# MMCSD register map
Vendor: Texas Instruments
Registers are 32-bit, access per field, no defined reset value unless marked. A register's access mark holds for its fields unless they carry their own. Offsets are as the file gives them; [hi:lo] are bit positions; 'fields as' and 'values as' point back to an identical list.

## MMCSD (part 2 of 2)
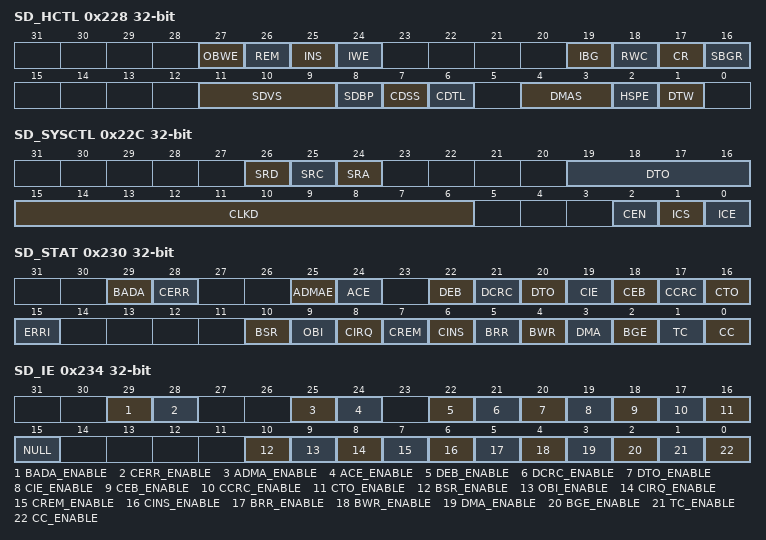
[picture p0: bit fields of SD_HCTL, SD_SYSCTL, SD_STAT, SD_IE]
0x228 SD_HCTL — This register defines the host controls to set power, wake-up and transfer parameters. SD_HCTL[31:24] = Wake-up control. SD_HCTL[23:16] = Block gap control. SD_HCTL[15:8] = Power control. SD_HCTL[7:0] = Host control. If your device does not support MMC cards, then those bits in this register which are meant for MMC card use should be assumed to be reserved.
  [27] OBWE rw — Wake-up event enable for 'out-of-band' Interrupt. [[br]]This bit enables wake-up events for 'out-of-band' assertion. [[br]]Wake-up is generated if the wake-up feature is enabled (SD_SYSCONFIG[2] ENAWAKEUP bit). [[br]]The write to this register is ignored when SD_CON[14] OBIE bit is not set.
    1=en_2_0x1 (Enable wake-up on 'out-of-band' Interrupt); 0=en_1_0x0 (Disable wake-up on 'out-of-band' Interrupt)
  [26] REM rw — Wake-up event enable on SD card removal. [[br]]This bit enables wake-up events for card removal assertion. [[br]]Wake-up is generated if the wake-up feature is enabled (SD_SYSCONFIG[2] ENAWAKEUP bit).
    1=en_2_0x1 (Enable wake-up on card removal); 0=en_1_0x0 (Disable wake-up on card removal)
  [25] INS rw — Wake-up event enable on SD card insertion This bit enables wake-up events for card insertion assertion. [[br]]Wake-up is generated if the wake-up feature is enabled (SD_SYSCONFIG[2] ENAWAKEUP bit).
    1=en_2_0x1 (Enable wake-up on card insertion); 0=en_1_0x0 (Disable wake-up on card insertion)
  [24] IWE rw — Wake-up event enable on SD card interrupt. [[br]]This bit enables wake-up events for card interrupt assertion. [[br]]Wake-up is generated if the wake-up feature is enabled (SD_SYSCONFIG[2] ENAWAKEUP bit) and enable status bit is set (SD_IE[8] CIRQ_ENABLE bit).
    1=en_2_0x1 (Enable wake-up on card interrupt); 0=en_1_0x0 (Disable wake-up on card interrupt)
  [19] IBG rw — Interrupt block at gap. [[br]]This bit is valid only in [[br]]4-bit mode of SDIO card to enable interrupt detection in the interrupt cycle at block gap for a multiple block transfer. [[br]]For MMC cards and for SD card this bit should be cleared to 0.
    1=en_2_0x1 (Enable interrupt detection at the block gap in 4-bit mode); 0=en_1_0x0 (Disable interrupt detection at the block gap in 4-bit mode)
  [18] RWC rw — Read wait control. [[br]]The read wait function is optional only for SDIO cards. [[br]]If the card supports read wait, this bit must be enabled, then requesting a stop at block gap (SD_HCTL[16] SBGR bit) generates a read wait period after the current end of block. [[br]]Be careful, if read wait is not supported it may cause a conflict on mmc_dat line.
    1=en_2_0x1 (Enable read wait control); 0=en_1_0x0 (Disable read wait control. Suspend/resume cannot be supported.)
  [17] CR rw — Continue request. [[br]]This bit is used to restart a transaction that was stopped by requesting a stop at block gap (SD_HCTL[16] SBGR bit). [[br]]Set this bit to 1 restarts the transfer. [[br]]The bit is automatically cleared to 0 by the host controller when transfer has restarted, that is, mmc_dat line is active (SD_PSTATE[2] DLA bit) or transferring data (SD_PSTATE[8] WTA bit). [[br]]The Stop at block gap request must be disabled (SD_HCTL[16] SBGR bit =0) before setting this bit.
    1=en_2_0x1 (Transfer restart); 0=en_1_0x0 (No affect)
  [16] SBGR rw — Stop at block gap request. [[br]]This bit is used to stop executing a transaction at the next block gap. [[br]]The transfer can restart with a continue request (SD_HCTL[17] CR bit) or during a suspend/resume sequence. [[br]]In case of read transfer, the card must support read wait control. [[br]]In case of write transfer, the host driver shall set this bit after all block data written. [[br]]Until the transfer completion (SD_STAT[1] TC bit set to 1), the host driver shall leave this bit set to 1.If this bit is set, the local host shall not write to the data register (SD_DATA).
    1=en_2_0x1 (Stop at block gap); 0=en_1_0x0 (Transfer mode)
  [11:9] SDVS rw — SD bus voltage select (All cards). [[br]]The host driver should set these bits to select the voltage level for the card according to the voltage supported by the system (SD_CAPA[26] VS18 bit, SD_CAPA[25] VS30 bit, SD_CAPA[24] VS33 bit) before starting a transfer. [[br]]If MMCSD[[br]]2: This field must be set to 5h. [[br]]If MMCSD[[br]]3: This field must be set to 5h.
    7=en_3_0x7 (3.3 V (Typical)); 6=en_2_0x6 (3.0 V (Typical)); 5=en_1_0x5 (1.8 V (Typical))
  [8] SDBP rw — SD bus power. [[br]]Before setting this bit, the host driver shall select the SD bus voltage (SD_HCTL[[br]][11:9] SDVS bits). [[br]]If the host controller detects the No card state, this bit is automatically cleared to 0. [[br]]If the module is power off, a write in the command register (SD_CMD) will not start the transfer. [[br]]A write to this bit has no effect if the selected SD bus voltage is not supported according to capability register (SD_CAPA[VS*]).
    1=en_2_0x1 (Power on); 0=en_1_0x0 (Power off)
  [7] CDSS rw — Card Detect Signal Selection. [[br]]This bit selects source for the card detection. [[br]]When the source for the card detection is switched, the interrupt should be disabled during the switching period by clearing the Interrupt Status/Signal Enable register in order to mask unexpected interrupt being caused by the glitch. [[br]]The Interrupt Status/Signal Enable should be disabled during over the period of debouncing. [[br]]
    1=en_2_0x1 (The Card Detect Test Level is selected (for test purposes).); 0=en_1_0x0 (SDCD# is selected (for normal use).)
  [6] CDTL rw — Card Detect Test Level. [[br]]This bit is enabled while the Card Detect Signal Selection is set to 1 and it indicates card inserted or not. [[br]]0 = No card [[br]]1 = Card inserted.
  [4:3] DMAS rw — DMA Select. [[br]]One of the supported DMA modes can be selected. [[br]]The host driver shall check support of DMA modes by referencing the Capabilities register. [[br]]Use of selected DMA is determined by DMA Enable of the Transfer Mode register. [[br]]This register is only meaningful when MADMA_EN is set to 1. [[br]]When MADMA_EN is cleared to 0 the bit field is read only and returned value is 0. [[br]]
    3=en_4_0x3 (Reserved); 2=en_3_0x2 (32-bit Address ADMA2 is selected.); 1=en_2_0x1 (Reserved); 0=en_1_0x0 (Reserved)
  [2] HSPE rw — High Speed Enable. [[br]]Before setting this bit, the Host Driver shall check the High Speed Support in the Capabilities register. [[br]]If this bit is cleared to 0 (default), the Host Controller outputs CMD line and DAT lines at the falling edge of the SD Clock. [[br]]If this bit is set to 1, the Host Controller outputs CMD line and DAT lines at the rising edge of the SD Clock. [[br]]This bit shall not be set when dual data rate mode is activated in SD_CON[DDR]. [[br]]
    1=en_2_0x1 (High speed mode); 0=en_1_0x0 (Normal speed mode)
  [1] DTW rw — Data transfer width. [[br]]This bit must be set following a valid SET_BUS_WIDTH command (ACMD6) with the value written in bit 1 of the argument. [[br]]Prior to this command, the SD card configuration register (SCR) must be verified for the supported bus width by the SD card. [[br]]
    1=en_2_0x1 (4-bit Data width (mmc_dat[3:0] used)); 0=en_1_0x0 (1-bit Data width (mmc_dat0 used))
0x22C SD_SYSCTL — This register defines the system controls to set software resets, clock frequency management and data timeout. SD_SYSCTL[31:24] = Software resets. SD_SYSCTL[23:16] = Timeout control. SD_SYSCTL[15:0] = Clock control.
  [26] SRD rw — Software reset for mmc_dat line. [[br]]This bit is set to 1 for reset and released to 0 when completed. [[br]]Due to additional implementation logic, the reset does not immediately start when asserted. [[br]]The proper procedure is: (a) Set to 1 to start reset, (b) Poll for 1 to identify start of reset, and (c) Poll for 0 to identify reset is complete. [[br]]mmc_dat finite state machine in both clock domain are also reset. [[br]]These registers are cleared by the SD_SYSCTL[26] SRD bit: SD_DATA. [[br]]SD_PSTATEBRE, BWE, RTA, WTA, DLA and DATI. [[br]]SD_HCTLSBGR and CR. [[br]]SD_STATBRR, BWR, BGE and TC Interconnect and MMC buffer data management is reinitialized. [[br]]Note: If a soft reset is issued when an interrupt is asserted, data may be lost.
    1=en_2_0x1 (Software reset for mmc_dat line); 0=en_1_0x0 (Reset completed)
  [25] SRC rw — Software reset for mmc_cmd line. [[br]]This bit is set to 1 for reset and released to 0 when completed. [[br]]Due to additional implementation logic, the reset does not immediately start when asserted. [[br]]The proper procedure is: (a) Set to 1 to start reset, (b) Poll for 1 to identify start of reset, and (c) Poll for 0 to identify reset is complete. [[br]]mmc_cmd finite state machine in both clock domain are also reset. [[br]]These registers are cleared by the SD_SYSCTL[25] SRC bit: SD_PSTATECMDI. [[br]]SD_STATCC Interconnect and MMC command status management is reinitialized. [[br]]Note: If a soft reset is issued when an interrupt is asserted, data may be lost.
    1=en_2_0x1 (Software reset for mmc_cmd line); 0=en_1_0x0 (Reset completed)
  [24] SRA rw — Software reset for all. [[br]]This bit is set to 1 for reset , and released to 0 when completed. [[br]]This reset affects the entire host controller except for the card detection circuit and capabilities registers.
    1=en_2_0x1 (Software reset for all the design); 0=en_1_0x0 (Reset completed)
  [19:16] DTO rw — Data timeout counter value and busy timeout. [[br]]This value determines the interval by which mmc_dat lines timeouts are detected. [[br]]The host driver needs to set this bit field based on: The maximum read access time (NAC) (Refer to the SD Specification Part1 Physical Layer). [[br]]The data read access time values (TAAC and NSAC) in the card specific data register (CSD) of the card. [[br]]The timeout clock base frequency (SD_CAPA[[br]][5:0] TCF bits). [[br]]If the card does not respond within the specified number of cycles, a data timeout error occurs (SD_STAT[20] DTO bit). [[br]]The SD_SYSCTL[19,16] DTO bit field is also used to check busy duration, to generate busy timeout for commands with busy response or for busy programming during a write command. [[br]]Timeout on CRC status is generated if no CRC token is present after a block write.
    15=en_4_0xF (Reserved); 14=en_3_0xE (TCF x 2^27); 1=en_2_0x1 (TCF x 2^14); 0=en_1_0x0 (TCF x 2^13)
  [15:6] CLKD rw — Clock frequency select. [[br]]These bits define the ratio between a reference clock frequency (system dependant) and the output clock frequency on the mmc_clk pin of either the memory card (MMC, SD, or SDIO).
    0x3FF=en_5_0x3FF (Clock Ref / 1023); 3=en_4_0x3 (Clock Ref / 3); 2=en_3_0x2 (Clock Ref / 2); 1=en_2_0x1 (Clock Ref bypass); 0=en_1_0x0 (Clock Ref bypass)
  [2] CEN rw — Clock enable. [[br]]This bit controls if the clock is provided to the card or not.
    1=en_2_0x1 (The clock is provided to the card and can be automatically gated when SD_SYSCONFIG[0] AUTOIDLE bit is set to 1 (default value). The host driver shall wait to set this bit to 1 until the Internal clock is stable (SD_SYSCTL[1] ICS bit).); 0=en_1_0x0 (The clock is not provided to the card . Clock frequency can be changed .)
  [1] ICS ro — Internal clock stable (status)This bit indicates either the internal clock is stable or not.
    1=en_2_0x1 (The internal clock is stable after enabling the clock (SD_SYSCTL[0] ICE bit) or after changing the clock ratio (SD_SYSCTL[15:6] CLKD bits).); 0=en_1_0x0 (The internal clock is not stable.)
  [0] ICE rw — Internal clock enable. [[br]]This register controls the internal clock activity. [[br]]In very low power state, the internal clock is stopped. [[br]]Note: The activity of the debounce clock (used for wake-up events) and the interface clock (used for reads and writes to the module register map) are not affected by this register.
    1=en_2_0x1 (The internal clock oscillates and can be automatically gated when SD_SYSCONFIG[0] AUTOIDLE bit is set to 1 (default value).); 0=en_1_0x0 (The internal clock is stopped (very low power state).)
0x230 SD_STAT — The interrupt status regroups all the status of the module internal events that can generate an interrupt. SD_STAT[31:16] = Error Interrupt Status. SD_STAT[15:0] = Normal Interrupt Status. The error bits are located in the upper 16 bits of the SD_STAT register. All bits are cleared by writing a 1 to them. Additionally, bits 15 and 8 serve as special error bits. These cannot be cleared by writing a 1 to them. Bit 15 (ERRI) is automatically cleared when the error causing to ERRI to be set is handled. (that is, when bits 31:16 are cleared, bit 15 will be automatically cleared). Bit 8 (CIRQ) is cleared by writing a 0 to SD_IE[8] (masking the interrupt) and servicing the interrupt.
  [29] BADA rw — Bad access to data space. [[br]]This bit is set automatically to indicate a bad access to buffer when not allowed: During a read access to the data register (SD_DATA) while buffer reads are not allowed (SD_PSTATE[11] BRE bit =0). [[br]]During a write access to the data register (SD_DATA) while buffer writes are not allowed (SD_PSTATE[10] BWE bit=0).
    1=en_4_0x1 (Status is cleared.); 1=en_3_0x1 (Bad access); 0=en_2_0x0 (No interrupt); 0=en_1_0x0 (Status bit unchanged)
  [28] CERR rw — Card error. [[br]]This bit is set automatically when there is at least one error in a response of type R1, R1b, R6, R5 or R5b. [[br]]Only bits referenced as type E (error) in status field in the response can set a card status error. [[br]]An error bit in the response is flagged only if corresponding bit in card status response error SD_CSRE in set. [[br]]There is no card error detection for autoCMD12 command. [[br]]The host driver shall read SD_RSP76 register to detect error bits in the command response.
    1=en_4_0x1 (Status is cleared.); 1=en_3_0x1 (Card error); 0=en_2_0x0 (No error); 0=en_1_0x0 (Status bit unchanged)
  [25] ADMAE rw — ADMA Error. [[br]]This bit is set when the Host Controller detects errors during ADMA based data transfer. [[br]]The state of the ADMA at an error occurrence is saved in the ADMA Error Status Register. [[br]]In addition, the Host Controller generates this interrupt when it detects invalid descriptor data (Valid=0) at the ST_FDS state. [[br]]ADMA Error State in the ADMA Error Status indicates that an error occurs in ST_FDS state. [[br]]The Host Driver may find that Valid bit is not set at the error descriptor. [[br]]
    1=en_4_0x1 (Status is cleared.); 1=en_3_0x1 (ADMA error); 0=en_2_0x0 (No interrupt); 0=en_1_0x0 (Status bit unchanged)
  [24] ACE rw — Auto CMD12 error. [[br]]This bit is set automatically when one of the bits in Auto CMD12 Error status register has changed from 0 to 1.
    1=en_4_0x1 (AutoCMD12 error); 1=en_3_0x1 (Status is cleared.); 0=en_2_0x0 (No error); 0=en_1_0x0 (Status bit unchanged)
  [22] DEB rw — Data End Bit error. [[br]]This bit is set automatically when detecting a 0 at the end bit position of read data on mmc_dat line or at the end position of the CRC status in write mode.
    1=en_4_0x1 (Status is cleared.); 1=en_3_0x1 (Data end bit error); 0=en_2_0x0 (No error); 0=en_1_0x0 (Status bit unchanged)
  [21] DCRC rw — Data CRC Error. [[br]]This bit is set automatically when there is a CRC16 error in the data phase response following a block read command or if there is a [[br]]3-bit CRC status different of a position "010" token during a block write command.
    1=en_4_0x1 (Status is cleared.); 1=en_3_0x1 (Data CRC error); 0=en_2_0x0 (No error); 0=en_1_0x0 (Status bit unchanged)
  [20] DTO rw — Data timeout error. [[br]]This bit is set automatically according to the following conditions: Busy timeout for R1b, R5b response type. [[br]]Busy timeout after write CRC status. [[br]]Write CRC status timeout. [[br]]Read data timeout.
    1=en_4_0x1 (Status is cleared.); 1=en_3_0x1 (Time out); 0=en_2_0x0 (No error); 0=en_1_0x0 (Status bit unchanged)
  [19] CIE rw — Command index error. [[br]]This bit is set automatically when response index differs from corresponding command index previously emitted. [[br]]It depends on the enable bit (SD_CMD[20] CICE).
    1=en_4_0x1 (Status is cleared.); 1=en_3_0x1 (Command index error); 0=en_2_0x0 (No error); 0=en_1_0x0 (Status bit unchanged)
  [18] CEB rw — Command end bit error. [[br]]This bit is set automatically when detecting a 0 at the end bit position of a command response.
    1=en_4_0x1 (Command end bit error); 1=en_3_0x1 (Status is cleared.); 0=en_2_0x0 (No error); 0=en_1_0x0 (Status bit unchanged)
  [17] CCRC rw — Command CRC error. [[br]]This bit is set automatically when there is a CRC7 error in the command response depending on the enable bit (SD_CMD[19] CCCE).
    1=en_4_0x1 (Status is cleared.); 1=en_3_0x1 (Command CRC error); 0=en_2_0x0 (No error); 0=en_1_0x0 (Status bit unchanged)
  [16] CTO rw — Command timeout error. [[br]]This bit is set automatically when no response is received within 64 clock cycles from the end bit of the command. [[br]]For commands that reply within 5 clock cycles - the timeout is still detected at 64 clock cycles.
    1=en_4_0x1 (Time Out); 1=en_3_0x1 (Status is cleared.); 0=en_2_0x0 (No error); 0=en_1_0x0 (Status bit unchanged)
  [15] ERRI ro — Error interrupt. [[br]]If any of the bits in the Error Interrupt Status register (SD_STAT[[br]][31:16]) are set, then this bit is set to 1. [[br]]Therefore the host driver can efficiently test for an error by checking this bit first. [[br]]Writes to this bit are ignored.
    1=en_2_0x1 (Error interrupt event(s) occurred); 0=en_1_0x0 (No interrupt)
  [10] BSR rw — Boot Status Received Interrupt. [[br]]This bit is set automatically when SD_CON[BOOT] is set 1 or 2 and a boot status is received on DAT[0] line. [[br]]This interrupt is only useful for MMC card.
    1=en_4_0x1 (Status is cleared.); 1=en_3_0x1 (Boot Status Received Interrupt occurred.); 0=en_2_0x0 (No interrupt); 0=en_1_0x0 (Status bit unchanged)
  [9] OBI ro — Out-of-band interrupt (This interrupt is only useful for MMC card). [[br]]This bit is set automatically when SD_CON[14] OBIE bit is set and an out-of-band interrupt occurs on OBI pin. [[br]]The interrupt detection depends on polarity controlled by SD_CON[13] OBIP bit. [[br]]The out-of-band interrupt signal is a system specific feature for future use, this signal is not required for existing specification implementation.
    1=en_4_0x1 (Status is cleared.); 1=en_3_0x1 (Interrupt out-of-band occurs); 0=en_2_0x0 (No out-of-band interrupt); 0=en_1_0x0 (Status bit unchanged)
  [8] CIRQ ro — Card interrupt. [[br]]This bit is only used for SD and SDIO cards. [[br]]In [[br]]1-bit mode, interrupt source is asynchronous (can be a source of asynchronous wake-up). [[br]]In [[br]]4-bit mode, interrupt source is sampled during the interrupt cycle. [[br]]In CE-ATA mode, interrupt source is detected when the card drives mmc_cmd line to zero during one cycle after data transmission end. [[br]]All modes above are fully exclusive. [[br]]The controller interrupt must be clear by setting SD_IE[8] CIRQ_ENABLE to 0, then the host driver must start the interrupt service with card (clearing card interrupt status) to remove card interrupt source. [[br]]Otherwise the Controller interrupt will be reasserted as soon as SD_IE[8] CIRQ_ENABLE is set to 1. [[br]]Writes to this bit are ignored.
    1=en_2_0x1 (Generate card interrupt); 0=en_1_0x0 (No card interrupt)
  [7] CREM rw — Card Removal. [[br]]This bit is set automatically when SD_PSTATE[CINS] changes from 1 to 0. [[br]]A clear of this bit doesn't affect Card inserted present state (SD_PSTATE[CINS]).
    1=en_4_0x1 (Status is cleared); 1=en_3_0x1 (Card Removed); 0=en_2_0x0 (Card State stable or debouncing); 0=en_1_0x0 (Status bit unchanged)
  [6] CINS rw — Card Insertion. [[br]]This bit is set automatically when SD_PSTATE[CINS] changes from 0 to 1. [[br]]A clear of this bit doesn't affect Card inserted present state (SD_PSTATE[CINS]).
    1=en_4_0x1 (Card inserted); 1=en_3_0x1 (Status is cleared.); 0=en_2_0x0 (Card State stable or debouncing); 0=en_1_0x0 (Status bit unchanged)
  [5] BRR rw — Buffer read ready. [[br]]This bit is set automatically during a read operation to the card (see class [[br]]2 - block oriented read commands) when one block specified by the SD_BLK[[br]][10:0] BLEN bit field is completely written in the buffer. [[br]]It indicates that the memory card has filled out the buffer and that the local host needs to empty the buffer by reading it. [[br]]Note: If the DMA receive-mode is enabled, this bit is never set[[br]] instead a DMA receive request to the main DMA controller of the system is generated.
    1=en_4_0x1 (Status is cleared.); 1=en_3_0x1 (Ready to read buffer); 0=en_2_0x0 (Not ready to read buffer); 0=en_1_0x0 (Status bit unchanged)
  [4] BWR rw — Buffer write ready. [[br]]This bit is set automatically during a write operation to the card (see class [[br]]4 - block oriented write command) when the host can write a complete block as specified by SD_BLK[[br]][10:0] BLEN. [[br]]It indicates that the memory card has emptied one block from the buffer and that the local host is able to write one block of data into the buffer. [[br]]Note: If the DMA transmit mode is enabled, this bit is never set[[br]] instead, a DMA transmit request to the main DMA controller of the system is generated.
    1=en_4_0x1 (Ready to write buffer); 1=en_3_0x1 (Status is cleared.); 0=en_2_0x0 (Not ready to write buffer); 0=en_1_0x0 (Status bit unchanged)
  [3] DMA rw — DMA Interrupt. [[br]]This status is set when an interrupt is required in the ADMA instruction and after the data transfer completion.
    1=en_4_0x1 (No DMA Interrupt); 1=en_3_0x1 (Status is cleared.); 0=en_2_0x0 (DMA Interrupt detected); 0=en_1_0x0 (Status bit unchanged)
  [2] BGE rw — Block gap event. [[br]]When a stop at block gap is requested (SD_HCTL[16] SBGR bit), this bit is automatically set when transaction is stopped at the block gap during a read or write operation. [[br]]
    1=en_4_0x1 (Transaction stopped at block gap); 1=en_3_0x1 (Status is cleared); 0=en_2_0x0 (No block gap event); 0=en_1_0x0 (Status bit unchanged)
  [1] TC rw — Transfer completed. [[br]]This bit is always set when a read/write transfer is completed or between two blocks when the transfer is stopped due to a stop at block gap request (SD_HCTL[16] SBGR bit). [[br]]
    1=en_4_0x1 (Data transfer complete); 1=en_3_0x1 (Status is cleared); 0=en_2_0x0 (No transfer complete); 0=en_1_0x0 (Status bit unchanged)
  [0] CC rw — Command complete. [[br]]This bit is set when a [[br]]1-to-0 transition occurs in the register command inhibit (SD_PSTATE[0] CMDI bit)
    1=en_4_0x1 (Command complete); 1=en_3_0x1 (Status is cleared); 0=en_2_0x0 (No command complete); 0=en_1_0x0 (Status bit unchanged)
0x234 SD_IE — This register allows to enable/disable the module to set status bits, on an event-by-event basis. SD_IE[31:16] = Error Interrupt Status Enable. SD_IE[15:0] = Normal Interrupt Status Enable.
  [29] BADA_ENABLE rw — Bad access to data space interrupt enable
    1=en_2_0x1 (Enabled); 0=en_1_0x0 (Masked)
  [28] CERR_ENABLE rw — Card error interrupt enable
    1=en_2_0x1 (Enabled); 0=en_1_0x0 (Masked)
  [25] ADMA_ENABLE rw — ADMA error Interrupt Enable
    1=en_2_0x1 (Enabled); 0=en_1_0x0 (Masked)
  [24] ACE_ENABLE rw — Auto CMD12 error interrupt enable
    1=en_2_0x1 (Enabled); 0=en_1_0x0 (Masked)
  [22] DEB_ENABLE rw — Data end bit error interrupt enable
    1=en_2_0x1 (Enabled); 0=en_1_0x0 (Masked)
  [21] DCRC_ENABLE rw — Data CRC error interrupt enable
    1=en_2_0x1 (Enabled); 0=en_1_0x0 (Masked)
  [20] DTO_ENABLE rw — Data timeout error interrupt enable
    1=en_2_0x1 (Enabled); 0=en_1_0x0 (Masked)
  [19] CIE_ENABLE rw — Command index error interrupt enable
    1=en_2_0x1 (Enabled); 0=en_1_0x0 (Masked)
  [18] CEB_ENABLE rw — Command end bit error interrupt enable
    1=en_2_0x1 (Enabled); 0=en_1_0x0 (Masked)
  [17] CCRC_ENABLE rw — Command CRC error interrupt enable
    1=en_2_0x1 (Enabled); 0=en_1_0x0 (Masked)
  [16] CTO_ENABLE rw — Command timeout error interrupt enable
    1=en_2_0x1 (Enabled); 0=en_1_0x0 (Masked)
  [15] NULL ro — Fixed to 0. [[br]]The host driver shall control error interrupts using the Error Interrupt Signal Enable register. [[br]]Writes to this bit are ignored.
  [10] BSR_ENABLE rw — Boot Status Interrupt Enable A write to this register when SD_CON[BOOT] is cleared to 0 is ignored.
    1=en_2_0x1 (Enabled); 0=en_1_0x0 (Masked)
  [9] OBI_ENABLE rw — Out-of-band interrupt enable A write to this register when SD_CON[14] OBIE is cleared to 0 is ignored.
    1=en_2_0x1 (Enabled); 0=en_1_0x0 (Masked)
  [8] CIRQ_ENABLE rw — Card interrupt enable. [[br]]A clear of this bit also clears the corresponding status bit. [[br]]During [[br]]1-bit mode, if the interrupt routine does not remove the source of a card interrupt in the SDIO card, the status bit is reasserted when this bit is set to 1. [[br]]This bit must be set to 1 when entering in smart idle mode to enable system to identity wake-up event and to allow controller to clear internal wake-up source.
    1=en_2_0x1 (Enabled); 0=en_1_0x0 (Masked)
  [7] CREM_ENABLE rw — Card Removal interrupt Enable This bit must be set to 1 when entering in smart idle mode to enable system to identity wake-up event and to allow controller to clear internal wake-up source. [[br]]
    1=en_2_0x1 (Enabled); 0=en_1_0x0 (Masked)
  [6] CINS_ENABLE rw — Card Insertion interrupt Enable This bit must be set to 1 when entering in smart idle mode to enable system to identity wake-up event and to allow controller to clear internal wake-up source. [[br]]
    1=en_2_0x1 (Enabled); 0=en_1_0x0 (Masked)
  [5] BRR_ENABLE rw — Buffer read ready interrupt enable
    1=en_2_0x1 (Enabled); 0=en_1_0x0 (Masked)
  [4] BWR_ENABLE rw — Buffer write ready interrupt enable
    1=en_2_0x1 (Enabled); 0=en_1_0x0 (Masked)
  [3] DMA_ENABLE rw — DMA interrupt enable
    1=en_2_0x1 (Enable); 0=en_1_0x0 (Masked)
  [2] BGE_ENABLE rw — Block gap event interrupt enable
    1=en_2_0x1 (Enabled); 0=en_1_0x0 (Masked)
  [1] TC_ENABLE rw — Transfer completed interrupt enable
    1=en_2_0x1 (Enabled); 0=en_1_0x0 (Masked)
  [0] CC_ENABLE rw — Command completed interrupt enable
    1=en_2_0x1 (Enabled); 0=en_1_0x0 (Masked)
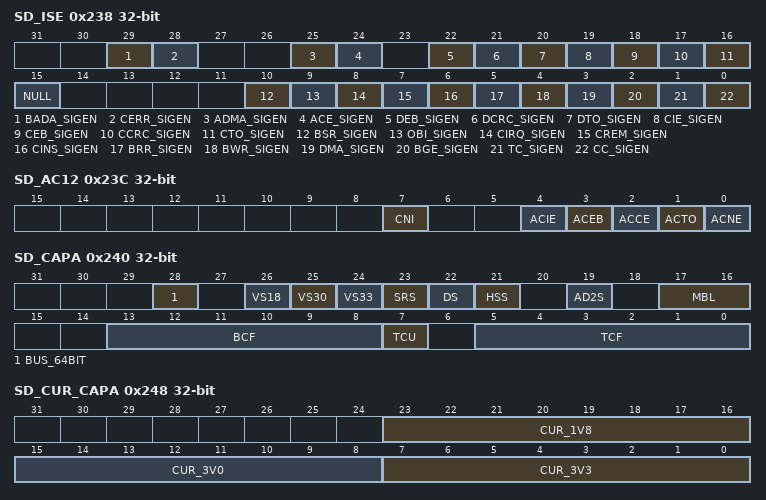
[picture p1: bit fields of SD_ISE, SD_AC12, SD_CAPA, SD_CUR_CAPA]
0x238 SD_ISE — This register allows you to enable/disable the module to set status bits, on an event-by-event basis. SD_ISE[31:16] = Error Interrupt Signal Enable. SD_ISE[15:0] = Normal Interrupt Signal Enable.
  [29] BADA_SIGEN rw — Bad access to data space interrupt enable
    1=en_2_0x1 (Enabled); 0=en_1_0x0 (Masked)
  [28] CERR_SIGEN rw — Card error interrupt signal status enable
    1=en_2_0x1 (Enabled); 0=en_1_0x0 (Masked)
  [25] ADMA_SIGEN rw — ADMA error signal status enable
    1=en_2_0x1 (Enabled); 0=en_1_0x0 (Masked)
  [24] ACE_SIGEN rw — Auto CMD12 error signal status enable
    1=en_2_0x1 (Enabled); 0=en_1_0x0 (Masked)
  [22] DEB_SIGEN rw — Data end bit error signal status enable
    1=en_2_0x1 (Enabled); 0=en_1_0x0 (Masked)
  [21] DCRC_SIGEN rw — Data CRC error signal status enable
    1=en_2_0x1 (Enabled); 0=en_1_0x0 (Masked)
  [20] DTO_SIGEN rw — Data timeout error signal status enable
    1=en_2_0x1 (Enabled); 0=en_1_0x0 (Masked. The host controller provides the clock to the card until the card sends the data or the transfer is aborted.)
  [19] CIE_SIGEN rw — Command index error signal status enable
    1=en_2_0x1 (Enabled); 0=en_1_0x0 (Masked)
  [18] CEB_SIGEN rw — Command end bit error signal status enable
    1=en_2_0x1 (Enabled); 0=en_1_0x0 (Masked)
  [17] CCRC_SIGEN rw — Command CRC error signal status enable
    1=en_2_0x1 (Enabled); 0=en_1_0x0 (Masked)
  [16] CTO_SIGEN rw — Command timeout error signal status enable
    1=en_2_0x1 (Enabled); 0=en_1_0x0 (Masked)
  [15] NULL ro — Fixed to 0. [[br]]The host driver shall control error interrupts using the error interrupt signal enable register. [[br]]Writes to this bit are ignored.
  [10] BSR_SIGEN rw — Boot Status signal status enable. [[br]]A write to this register when SD_CON[BOOT] is cleared to 0 is ignored
    1=en_2_0x1 (Enabled); 0=en_1_0x0 (Masked)
  [9] OBI_SIGEN rw — Out-of-band interrupt signal status enable. [[br]]A write to this register when SD_CON[14] OBIE is cleared to 0 is ignored.
    1=en_2_0x1 (Enabled); 0=en_1_0x0 (Masked)
  [8] CIRQ_SIGEN rw — Card interrupt signal status enable. [[br]]A clear of this bit also clears the corresponding status bit. [[br]]During [[br]]1-bit mode, if the interrupt routine does not remove the source of a card interrupt in the SDIO card, the status bit is reasserted when this bit is set to 1. [[br]]This bit must be set to 1 when entering in smart idle mode to enable system to identity wake-up event and to allow controller to clear internal wake-up source. [[br]]
    1=en_2_0x1 (Enabled); 0=en_1_0x0 (Masked)
  [7] CREM_SIGEN rw — Card Removal signal status enable This bit must be set to 1 when entering in smart idle mode to enable system to identity wake-up event and to allow controller to clear internal wake-up source. [[br]]
    1=en_2_0x1 (Enabled); 0=en_1_0x0 (Masked)
  [6] CINS_SIGEN rw — Card Insertion signal status enable. [[br]]This bit must be set to 1 when entering in smart idle mode to enable system to identity wake-up event and to allow controller to clear internal wake-up source. [[br]]
    1=en_2_0x1 (Enabled); 0=en_1_0x0 (Masked)
  [5] BRR_SIGEN rw — Buffer read ready signal status enable
    1=en_2_0x1 (Enabled); 0=en_1_0x0 (Masked)
  [4] BWR_SIGEN rw — Buffer write ready signal status enable
    1=en_2_0x1 (Enabled); 0=en_1_0x0 (Masked)
  [3] DMA_SIGEN rw — DMA signal status enable
    1=en_2_0x1 (Enabled); 0=en_1_0x0 (Masked)
  [2] BGE_SIGEN rw — Block gap event signal status enable
    1=en_2_0x1 (Enabled); 0=en_1_0x0 (Masked)
  [1] TC_SIGEN rw — Transfer completed signal status enable
    1=en_2_0x1 (Enabled); 0=en_1_0x0 (Masked)
  [0] CC_SIGEN rw — Command completed signal status enable
    1=en_2_0x1 (Enabled); 0=en_1_0x0 (Masked)
0x23C SD_AC12 ro — The host driver may determine which of the errors cases related to Auto CMD12 has occurred by checking this SD_AC12 register when an auto CMD12 error interrupt occurs. This register is valid only when auto CMD12 is enabled (SD_CMD[2] ACEN bit) and auto CMD12Error (SD_STAT[24] ACE bit) is set to 1. These bits are automatically reset when starting a new adtc command with data.
  [7] CNI — Command not issue by auto CMD12 error. [[br]]If this bit is set to 1, it means that pending command is not executed due to auto CMD12 error ACEB, ACCE, ACTO, or ACNE.
    1=en_2_0x1 (Command not issued); 0=en_1_0x0 (Not error)
  [4] ACIE — Auto CMD12 index error. [[br]]This bit is a set to 1 when response index differs from corresponding command auto CMD12 index previously emitted. [[br]]This bit depends on the command index check enable (SD_CMD[20] CICE bit).
    1=en_2_0x1 (Auto CMD12 index error); 0=en_1_0x0 (No error)
  [3] ACEB — Auto CMD12 end bit error. [[br]]This bit is set to 1 when detecting a 0 at the end bit position of auto CMD12 command response.
    1=en_2_0x1 (AutoCMD12 end bit error); 0=en_1_0x0 (No error)
  [2] ACCE — Auto CMD12 CRC error. [[br]]This bit is automatically set to 1 when a CRC7 error is detected in the auto CMD12 command response depending on the enable in the SD_CMD[19] CCCE bit.
    1=en_2_0x1 (Auto CMD12 CRC error); 0=en_1_0x0 (No error)
  [1] ACTO — Auto CMD12 timeout error. [[br]]This bit is set to 1 if no response is received within 64 clock cycles from the end bit of the auto CMD12 command.
    1=en_2_0x1 (Auto CMD12 time out); 0=en_1_0x0 (No error)
  [0] ACNE — Auto CMD12 not executed. [[br]]This bit is set to 1 if multiple block data transfer command has started and if an error occurs in command before auto CMD12 starts.
    1=en_2_0x1 (Auto CMD12 not executed); 0=en_1_0x0 (Auto CMD12 executed)
0x240 SD_CAPA — This register lists the capabilities of the MMC/SD/SDIO host controller.
  [28] BUS_64BIT rw — 64 Bit System Bus Support. [[br]]Setting 1 to this bit indicates that the Host Controller supports [[br]]64-bit address descriptor mode and is connected to [[br]]64-bit address system bus.
    1=en_2_0x1 (64-bit System bus address); 0=en_1_0x0 (32-bit System bus address)
  [26] VS18 rw — Voltage support 1.8 V. [[br]]Initialization of this register (via a write access to this register) depends on the system capabilities. [[br]]The host driver shall not modify this register after the initialization. [[br]]This register is only reinitialized by a hard reset (via mmc_RESET signal).
    1=en_4_0x1 (1.8 V supported); 1=en_3_0x1 (1.8 V supported); 0=en_2_0x0 (1.8 V not supported); 0=en_1_0x0 (1.8 V not supported)
  [25] VS30 rw — Voltage support 3.0V. [[br]]Initialization of this register (via a write access to this register) depends on the system capabilities. [[br]]The host driver shall not modify this register after the initialization. [[br]]This register is only reinitialized by a hard reset (via mmc_RESET signal).
    1=en_4_0x1 (3.0 V supported); 1=en_3_0x1 (3.0 V supported); 0=en_2_0x0 (3.0 V not supported); 0=en_1_0x0 (3.0 V not supported)
  [24] VS33 rw — Voltage support 3.3V. [[br]]Initialization of this register (via a write access to this register) depends on the system capabilities. [[br]]The host driver shall not modify this register after the initialization. [[br]]This register is only reinitialized by a hard reset (via mmc_RESET signal).
    1=en_4_0x1 (3.3 V supported); 1=en_3_0x1 (3.3 V supported); 0=en_2_0x0 (3.3 V not supported); 0=en_1_0x0 (3.3 V not supported)
  [23] SRS ro — Suspend/resume support (SDIO cards only). [[br]]This bit indicates whether the host controller supports Suspend/Resume functionality.
    1=en_2_0x1 (The Host controller supports suspend/resume functionality.); 0=en_1_0x0 (The Host controller does not suspend/resume functionality.)
  [22] DS ro — DMA support. [[br]]This bit indicates that the Host controller is able to use DMA to transfer data between system memory and the Host controller directly.
    1=en_2_0x1 (DMA supported); 0=en_1_0x0 (DMA not supported)
  [21] HSS ro — High-speed support. [[br]]This bit indicates that the host controller supports high speed operations and can supply an up-to-52 MHz clock to the card.
    1=en_2_0x1 (DMA supported); 0=en_1_0x0 (DMA not supported)
  [19] AD2S ro — This bit indicates whether the Host Controller is capable of using ADMA2. [[br]]It depends on setting of generic parameter MADMA_EN.
    1=en_2_0x1 (ADMA2 not supported); 0=en_1_0x0 (ADMA2 supported)
  [17:16] MBL ro — Maximum block length. [[br]]This value indicates the maximum block size that the host driver can read and write to the buffer in the host controller. [[br]]The host controller supports 512 bytes and 1024 bytes block transfers.
    2=en_3_0x2 (2048 bytes); 1=en_2_0x1 (1024 bytes); 0=en_1_0x0 (512 bytes)
  [13:8] BCF ro — Base clock frequency for clock provided to the card. [[br]]ARRAY(0x1bfe1b0)
  [7] TCU ro — Timeout clock unit. [[br]]This bit shows the unit of base clock frequency used to detect Data Timeout Error (SD_STAT[20] DTO bit).
    1=en_2_0x1 (MHz); 0=en_1_0x0 (kHz)
  [5:0] TCF ro — Timeout clock frequency. [[br]]The timeout clock frequency is used to detect Data Timeout Error (SD_STAT[20] DTO bit).
    0=en_1_0x0 (The timeout clock frequency depends on the frequency of the clock provided to the card. The value of the timeout clock frequency is not available in this register.)
0x248 SD_CUR_CAPA — This register indicates the maximum current capability for each voltage. The value is meaningful if the voltage support is set in the capabilities register (SD_CAPA). Initialization of this register (via a write access to this register) depends on the system capabilities. The host driver shall not modify this register after the initialization. This register is only reinitialized by a hard reset (via mmc_RESET signal).
  [all] fields
    0=en_1_0x0 (The maximum current capability for this voltage is not available. Feature not implemented.)
  [23:16] CUR_1V8 rw — Maximum current for 1.8 V
  [15:8] CUR_3V0 rw — Maximum current for 3.0 V
  [7:0] CUR_3V3 rw — Maximum current for 3.3 V
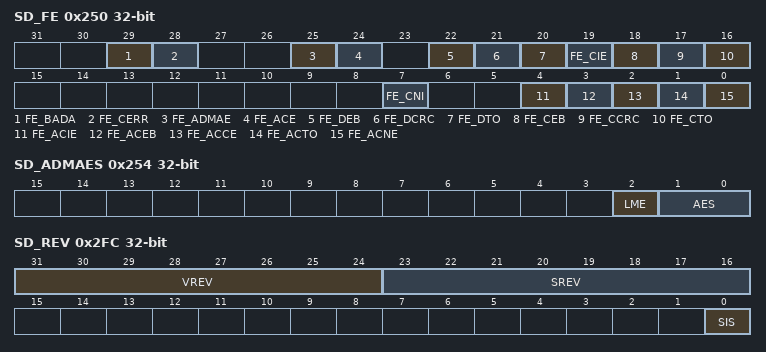
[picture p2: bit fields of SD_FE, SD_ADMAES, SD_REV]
0x250 SD_FE — The Force Event register is not a physically implemented register. Rather, it is an address at which the Error Interrupt Status register can be written. The effect of a write to this address will be reflected in the Error Interrupt Status Register, if corresponding bit of the Error Interrupt Status Enable Register is set.
  [29] FE_BADA wo — Force Event Bad access to data space.
    1=en_2_0x1 (Interrupt forced.); 0=en_1_0x0 (No effect; no interrupt)
  [28] FE_CERR wo — Force Event Card error
    values as FE_BADA
  [25] FE_ADMAE wo — Force Event ADMA error
    values as FE_BADA
  [24] FE_ACE wo — Force Event Auto CMD12 error.
    values as FE_BADA
  [22] FE_DEB wo — Force Event Data End Bit error.
    values as FE_BADA
  [21] FE_DCRC wo — Force Event Data CRC error
    values as FE_BADA
  [20] FE_DTO wo — Force Event Data timeout error
    values as FE_BADA
  [19] FE_CIE wo — Force Event Command index error
    values as FE_BADA
  [18] FE_CEB wo — Force Event Command end bit error
    values as FE_BADA
  [17] FE_CCRC wo — Force Event Comemand CRC error
    values as FE_BADA
  [16] FE_CTO wo — Force Event Command Timeout error
    values as FE_BADA
  [7] FE_CNI wo — Force Event Command not issue by Auto CMD12 error
    values as FE_BADA
  [4] FE_ACIE wo — Force Event Auto CMD12 index error
    values as FE_BADA
  [3] FE_ACEB wo — Force Event Auto CMD12 end bit error
    values as FE_BADA
  [2] FE_ACCE wo — Force Event Auto CMD12 CRC error
    values as FE_BADA
  [1] FE_ACTO wo — Force Event Auto CMD12 timeout error
    values as FE_BADA
  [0] FE_ACNE wo — Force Event Auto CMD12 not executed.
    1=en_2_0x1 (Interrupt forced.); 0=en_1_0x0 (No effect; no interrupt.)
0x254 SD_ADMAES — When an ADMA Error Interrupt has occurred, the ADMA Error States field in this register holds the ADMA state and the ADMA System Address Register holds the address around the error descriptor. For recovering the error, the Host Driver requires the ADMA state to identify the error descriptor address as follows: ST_STOP: Previous location set in the ADMA System Address register is the error descriptor address. ST_FDS: Current location set in the ADMA System Address register is the error descriptor address. ST_CADR: This sate is never set because do not generate ADMA error in this state. ST_TFR: Previous location set in the ADMA System Address register is the error descriptor address. In the case of a write operation, the Host Driver should use ACMD22 to get the number of written block rather than using this information, since unwritten data may exist in the Host Controller. The Host Controller generates the ADMA Error Interrupt when it detects invalid descriptor data (Valid = 0) at the ST_FDS state. In this case, ADMA Error State indicates that an error occurs at ST_FDS state. The Host Driver may find that the Valid bit is not set in the error descriptor.
  [2] LME wo — ADMA Length Mismatch Error: While Block Count Enable is being set, the total data length specified by the Descriptor table is different from that specified by the Block Count and Block Length. [[br]]Total data length cannot be divided by the block length.
    1=en_2_0x1 (Error); 0=en_1_0x0 (No error)
  [1:0] AES rw — ADMA Error State. [[br]]This field indicates the state of ADMA when an error occurred during an ADMA data transfer. [[br]]This field never indicates "10" because ADMA never stops in this state. [[br]]
    3=en_4_0x3 (ST_TFR (Transfer Data). Points to the 'next' of the error descriptor.); 2=en_3_0x2 (Never set this state. (Not used)); 1=en_2_0x1 (ST_STOP (Stop DMA). Points to the error descriptor.); 0=en_1_0x0 (ST_STOP (Stop DMA). Contents of the SYS_SDR register)
0x258 SD_ADMASAL rw — This register holds the byte address of the executing command of the Descriptor table. The 32-bit Address Descriptor uses the lower 32 bits of this register. At the start of ADMA, the Host Driver shall set the start address of the Descriptor table.
  [31:0] ADMA_A32B — The ADMA increments this register address, which points to the next line, whenever fetching a Descriptor line. [[br]]When the ADMA Error Interrupt is generated, this register holds the valid Descriptor address depending on the ADMA state. [[br]]The Host Driver shall program the Descriptor Table on a 32-bit boundary and set the 32-bit boundary address to this register. [[br]]ADMA2 ignores the lower 2 bits of this register and assumes it to be 00b. [[br]]
0x25C SD_ADMASAH rw
  [31:0] ADMA_A32B
0x2FC SD_REV ro — This register contains the hard coded RTL vendor revision number, the version number of SD specification compliancy and a slot status bit. SD_REV[31:16] = Host Controller Version. SD_REV[15:0] = Slot Interrupt Status.
  [31:24] VREV — Vendor Version Number. [[br]]Bits [[br]][7:4] is the major revision, bits [[br]][3:0] is the minor revision. [[br]]Examples: 10h for 1.0 21h for 2.1
  [23:16] SREV — Specification Version Number. [[br]]This status indicates the Standard SD Host Controller Specification Version. [[br]]The upper and lower [[br]]4-bits indicate the version.
    0=en_1_0x0 (SD Host Specification Version 1.0)
  [0] SIS — Slot Interrupt Status. [[br]]This status bit indicates the inverted state of interrupt signal for the module. [[br]]By a power on reset or by setting a software reset for all (SD_SYSCTL[24] SRA), the interrupt signal shall be deasserted and this status shall read 0.
    1=en_2_0x1 (Interrupt signal asserted.); 0=en_1_0x0 (Interrupt signal deasserted.)
